# MK50DZ10 register map
Vendor: Freescale Semiconductor, Inc.; Series: Kinetis_K; File version: 1.6
CPU: CM4 r0p1, little endian, no MPU, no FPU, VTOR, 4 interrupt priority bits
Registers are 32-bit, read-write, reset 0x0 unless marked. A register's access mark holds for its fields unless they carry their own. Offsets are from the block's base; [hi:lo] are bit positions; {n}, {i} and the like mark numbered series; 'fields as' and 'values as' point back to an identical list.

## AXBS — Crossbar switch
Base 0x40004000; register names take the prefix AXBS_
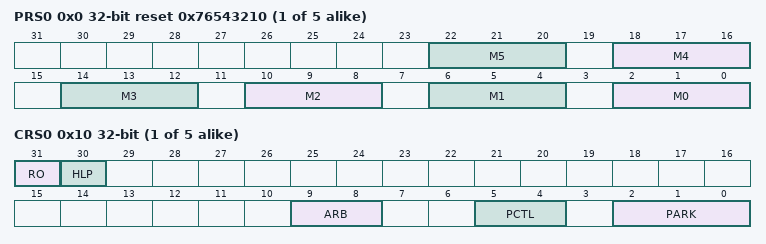
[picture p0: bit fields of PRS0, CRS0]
{0x0+0x100*i} PRS{i} (i=0..4) reset 0x76543210 — Priority Registers Slave
  [all] fields
    0=This master has level 1, or highest, priority when accessing the slave port; {v}=This master has level {v+1} priority when accessing the slave port (v=1..6); 7=This master has level 8, or lowest, priority when accessing the slave port
  [4n+2:4n] M{n} (n=0..5) — Master {n} priority. Sets the arbitration priority for this port on the associated slave port.
{0x10+0x100*i} CRS{i} (i=0..4) — Control Register
  [31] RO — Read only
    0=The slave port's registers are writeable; 1=The slave port's registers are read-only and cannot be written. Attempted writes have no effect on the registers and result in a bus error response.
  [30] HLP — Halt low priority
    0=The low power mode request has the highest priority for arbitration on this slave port; 1=The low power mode request has the lowest initial priority for arbitration on this slave port
  [9:8] ARB — Arbitration mode
    0=Fixed priority; 1=Round-robin, or rotating, priority
  [5:4] PCTL — Parking control
    0=When no master makes a request, the arbiter parks the slave port on the master port defined by the PARK bit field; 1=When no master makes a request, the arbiter parks the slave port on the last master to be in control of the slave port; 2=When no master makes a request, the slave port is not parked on a master and the arbiter drives all outputs to a constant safe state
  [2:0] PARK
    {v}=Park on master port M{v} (v=0..5)
{0x800+0x100*i} MGPCR{i} (i=0..2) — Master General Purpose Control Register
  [2:0] AULB — Arbitrates on undefined length bursts
    0=No arbitration is allowed during an undefined length burst; 1=Arbitration is allowed at any time during an undefined length burst; 2=Arbitration is allowed after four beats of an undefined length burst; 3=Arbitration is allowed after eight beats of an undefined length burst; 4=Arbitration is allowed after 16 beats of an undefined length burst
0xC00 MGPCR4 — Master General Purpose Control Register
  fields as MGPCR0
0xD00 MGPCR5 — Master General Purpose Control Register
  fields as MGPCR0

## MPU — Memory protection unit
Base 0x4000D000; register names take the prefix MPU_
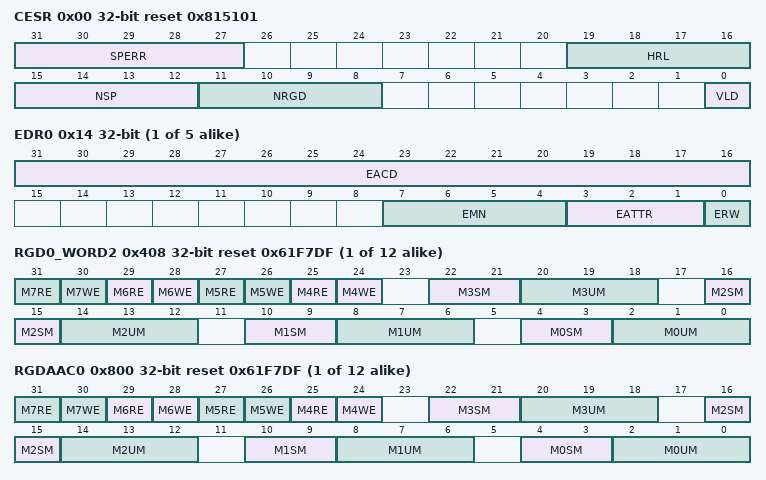
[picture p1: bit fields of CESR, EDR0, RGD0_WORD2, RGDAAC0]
0x00 CESR reset 0x815101 — Control/Error Status Register
  [31:27] SPERR — Slave port n error
    0=No error has occurred for slave port n; 1=An error has occurred for slave port n
  [19:16] HRL ro — Hardware revision level
  [15:12] NSP ro — Number of slave ports
  [11:8] NRGD ro — Number of region descriptors
    0=8 region descriptors; 1=12 region descriptors; 2=16 region descriptors
  [0] VLD — Valid (global enable/disable for the MPU)
    0=MPU is disabled. All accesses from all bus masters are allowed.; 1=MPU is enabled
{0x10+8i} EAR{i} (i=0..4) ro reset not defined — Error Address Register, Slave Port n
  [31:0] EADDR — Error address
{0x14+8i} EDR{i} (i=0..4) ro reset not defined — Error Detail Register, Slave Port n
  [31:16] EACD — Error access control detail
  [7:4] EMN — Error master number
  [3:1] EATTR — Error attributes
    0=User mode, instruction access; 1=User mode, data access; 2=Supervisor mode, instruction access; 3=Supervisor mode, data access
  [0] ERW — Error read/write
    0=Read; 1=Write
{0x400+0x10*i} RGD{i}_WORD0 (i=0..11) — Region Descriptor n, Word 0
  [31:5] SRTADDR — Start address
{0x404+0x10*i} RGD{i}_WORD1 (i=0..11) reset 0xFFFFFFFF — Region Descriptor n, Word 1
  [31:5] ENDADDR — End address
{0x408+0x10*i} RGD{i}_WORD2 (i=0..11) reset 0x61F7DF — Region Descriptor n, Word 2
  [2n+17] M{n}RE (n=4..7) — Bus master {n} read enable.
    0=Bus master {n} reads terminate with an access error and the read is not performed; 1=Bus master {n} reads allowed
  [2n+16] M{n}WE (n=4..7) — Bus master {n} write enable
    0=Bus master {n} writes terminate with an access error and the write is not performed; 1=Bus master {n} writes allowed
  [22:21] M3SM — Bus master 3 supervisor mode access control
    0=r/w/x; read, write and execute allowed; 1=r/x; read and execute allowed, but no write; 2=r/w; read and write allowed, but no execute; 3=Same as user mode defined in M3UM
  [20:18] M3UM — Bus master 3 user mode access control
    0=An attempted access of that mode may be terminated with an access error (if not allowed by another descriptor) and the access not performed; 1=Allows the given access type to occur
  [16:15] M2SM — Bus master 2 supervisor mode access control
  [14:12] M2UM — Bus master 2 user mode access control
  [10:9] M1SM — Bus master 1 supervisor mode access control
  [8:6] M1UM — Bus master 1 user mode access control
  [4:3] M0SM — Bus master 0 supervisor mode access control
  [2:0] M0UM — Bus master 0 user mode access control
{0x40C+0x10*i} RGD{i}_WORD3 (i=0..11) reset 0x1 — Region Descriptor n, Word 3
  [0] VLD — Valid
    0=Region descriptor is invalid; 1=Region descriptor is valid
{0x800+4i} RGDAAC{i} (i=0..11) reset 0x61F7DF — Region Descriptor Alternate Access Control n
  fields as RGD0_WORD2

## Notices in the file
Redistribution and use in source and binary forms, with or without modification,
are permitted provided that the following conditions are met:
o Redistributions of source code must retain the above copyright notice, this list
of conditions and the following disclaimer.
o Redistributions in binary form must reproduce the above copyright notice, this
list of conditions and the following disclaimer in the documentation and/or
other materials provided with the distribution.
o Neither the name of Freescale Semiconductor, Inc. nor the names of its
contributors may be used to endorse or promote products derived from this
software without specific prior written permission.
THIS SOFTWARE IS PROVIDED BY THE COPYRIGHT HOLDERS AND CONTRIBUTORS "AS IS" AND
ANY EXPRESS OR IMPLIED WARRANTIES, INCLUDING, BUT NOT LIMITED TO, THE IMPLIED
WARRANTIES OF MERCHANTABILITY AND FITNESS FOR A PARTICULAR PURPOSE ARE
DISCLAIMED. IN NO EVENT SHALL THE COPYRIGHT HOLDER OR CONTRIBUTORS BE LIABLE FOR
ANY DIRECT, INDIRECT, INCIDENTAL, SPECIAL, EXEMPLARY, OR CONSEQUENTIAL DAMAGES
(INCLUDING, BUT NOT LIMITED TO, PROCUREMENT OF SUBSTITUTE GOODS OR SERVICES;
LOSS OF USE, DATA, OR PROFITS; OR BUSINESS INTERRUPTION) HOWEVER CAUSED AND ON
ANY THEORY OF LIABILITY, WHETHER IN CONTRACT, STRICT LIABILITY, OR TORT
(INCLUDING NEGLIGENCE OR OTHERWISE) ARISING IN ANY WAY OUT OF THE USE OF THIS
SOFTWARE, EVEN IF ADVISED OF THE POSSIBILITY OF SUCH DAMAGE.
